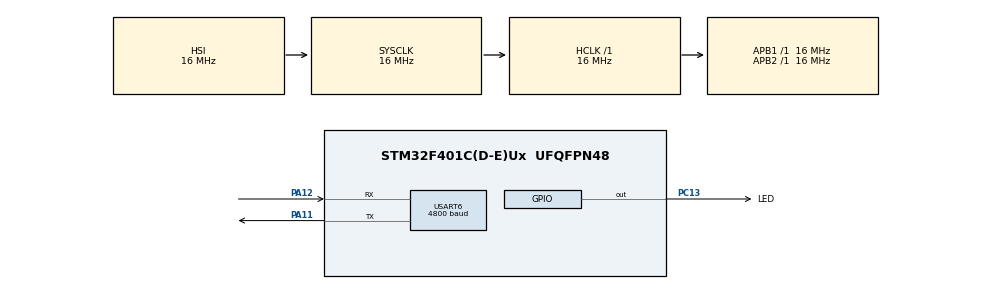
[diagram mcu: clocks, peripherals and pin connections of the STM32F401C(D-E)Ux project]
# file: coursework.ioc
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Mcu.Family=STM32F4
Mcu.Name=STM32F401C(D-E)Ux
Mcu.Package=UFQFPN48
NVIC.PriorityGroup=NVIC_PRIORITYGROUP_4
NVIC.USART6_IRQn=true\:0\:0\:false\:false\:true\:true\:true\:true
PA11.Mode=Asynchronous
PA11.Signal=USART6_TX
PA12.Mode=Asynchronous
PA12.Signal=USART6_RX
PC13-ANTI_TAMP.GPIO_Label=LED
PC13-ANTI_TAMP.GPIO_PuPd=GPIO_NOPULL
PC13-ANTI_TAMP.PinState=GPIO_PIN_RESET
PC13-ANTI_TAMP.Signal=GPIO_Output
ProjectManager.HeapSize=0x200
ProjectManager.StackSize=0x400
ProjectManager.TargetToolchain=STM32CubeIDE
RCC.AHBFreq_Value=16000000
RCC.APB1Freq_Value=16000000
RCC.APB2Freq_Value=16000000
RCC.CortexFreq_Value=16000000
RCC.HSE_VALUE=25000000
RCC.HSI_VALUE=16000000
RCC.LSE_VALUE=32768
RCC.SYSCLKFreq_VALUE=16000000
RCC.VCOOutputFreq_Value=192000000
USART6.BaudRate=4800
USART6.Parity=PARITY_EVEN
USART6.VirtualMode=VM_ASYNC
board=custom

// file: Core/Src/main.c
/* USER CODE BEGIN Header */
/**
  ******************************************************************************
  * @file           : main.c
  * @brief          : Main program body
  ******************************************************************************
  * @attention
  *
  * Copyright (c) 2023 STMicroelectronics.
  * All rights reserved.
  *
  * This software is licensed under terms that can be found in the LICENSE file
  * in the root directory of this software component.
  * If no LICENSE file comes with this software, it is provided AS-IS.
  *
  ******************************************************************************
  */
/* USER CODE END Header */
#include "main.h"

/* USER CODE BEGIN Includes */
#include "stdint.h"
/* USER CODE END Includes */

UART_HandleTypeDef huart6;

void SystemClock_Config(void);
static void MX_GPIO_Init(void);
static void MX_USART6_UART_Init(void);

int main(void)
{

  /* MCU Configuration--------------------------------------------------------*/

  /* Reset of all peripherals, Initializes the Flash interface and the Systick. */
  HAL_Init();

  /* USER CODE BEGIN Init */
  void print(const uint8_t * val, const uint8_t size){
  	  HAL_UART_Transmit_IT(&huart6, val, size);
  	  while( HAL_UART_GetState(&huart6) == HAL_UART_STATE_BUSY_TX );
  }

  void read(uint8_t * val, const uint8_t size){
  	  HAL_UART_Receive_IT(&huart6, val, size);
  	  while( HAL_UART_GetState(&huart6) == HAL_UART_STATE_BUSY_RX );
  }

  /* USER CODE END Init */

  /* Configure the system clock */
  SystemClock_Config();

  /* Initialize all configured peripherals */
  MX_GPIO_Init();
  MX_USART6_UART_Init();
  /* USER CODE BEGIN 2 */

  uint8_t output1[] = "\r\n*----------------------------------------------------*\r\nSelect work mode:"
		  "\r\n1.Switch led on"
		  "\r\n2.Switch led off"
		  "\r\n3.Blink led n times"
		  "\r\n4.Blink led n times with given periodicity"
		  "\r\n5.Exit the program"
		  "\r\nEnter an integer for work mode: ";
  uint8_t output2[] = "\r\nEnter an integer for n(<9): ";
  uint8_t output3[] = "\r\nYour input: ";
  uint8_t output4[] = "\r\n\r\nError: Incorrect input";
  uint8_t output5[] = "\r\nPress any key to continue...";
  uint8_t output6[] = "\r\nHow many times?:";
  uint8_t output7[] = "\r\nHow fast? (N*100 ms):";
  uint8_t input;
  uint8_t n;
  uint8_t x;

  /* USER CODE END 2 */

  /* Infinite loop */
  /* USER CODE BEGIN WHILE */
  HAL_GPIO_WritePin(LED_GPIO_Port, LED_Pin, GPIO_PIN_SET);
  while (1)
  {
	  print(output1, sizeof(output1));

	  read(&input, 1);

	  print(output3, sizeof(output3));
	  print(&input, 1);

	  if(input == '5')
		  break;

	  switch(input){
		  case '1':
			  HAL_GPIO_WritePin(LED_GPIO_Port, LED_Pin, GPIO_PIN_RESET);
			  break;

		  case '2':
			  HAL_GPIO_WritePin(LED_GPIO_Port, LED_Pin, GPIO_PIN_SET);
			  break;

		  case '3':
			  print(output2, sizeof(output2));
			  read(&n, 1);
			  print(output3, sizeof(output3));
			  print(&n, 1);
			  x = n-'0';
			  //HAL_GPIO_WritePin(LED_GPIO_Port, LED_Pin, GPIO_PIN_SET);
			  for(int i = 0; i < x; i++){
				  HAL_GPIO_WritePin(LED_GPIO_Port, LED_Pin, GPIO_PIN_SET);
				  HAL_Delay(500);
				  HAL_GPIO_WritePin(LED_GPIO_Port, LED_Pin, GPIO_PIN_RESET);
				  HAL_Delay(500);
			  }
			  HAL_GPIO_WritePin(LED_GPIO_Port, LED_Pin, GPIO_PIN_SET);
			  break;

		  case '4':
			  print(output6, sizeof(output6));
			  read(&n, 1);
			  print(output3, sizeof(output3));
			  print(&n, 1);
			  x = n - '0';

			  uint8_t per, per1;
			  print(output7, sizeof(output7));
			  read(&per, 1);
			  print(output3, sizeof(output3));
			  print(&per, 1);
			  per1 = per - '0';

			  for(int i = 0; i < x; i++){
				  HAL_GPIO_WritePin(LED_GPIO_Port, LED_Pin, GPIO_PIN_SET);
				  HAL_Delay(per1*100);
				  HAL_GPIO_WritePin(LED_GPIO_Port, LED_Pin, GPIO_PIN_RESET);
				  HAL_Delay(per1*100);
			  }
			  HAL_GPIO_WritePin(LED_GPIO_Port, LED_Pin, GPIO_PIN_SET);
			  break;

		  default:
			  print(output4, sizeof(output4));			//Incorrect input
			  continue;
	  }

	  print(output5, sizeof(output5));					//Press any key

	  read(&input, 1);

    /* USER CODE END WHILE */

  }
}

void SystemClock_Config(void)
{
  RCC_OscInitTypeDef RCC_OscInitStruct = {0};
  RCC_ClkInitTypeDef RCC_ClkInitStruct = {0};

  /** Configure the main internal regulator output voltage
  */
  __HAL_RCC_PWR_CLK_ENABLE();
  __HAL_PWR_VOLTAGESCALING_CONFIG(PWR_REGULATOR_VOLTAGE_SCALE2);

  /** Initializes the RCC Oscillators according to the specified parameters
  * in the RCC_OscInitTypeDef structure.
  */
  RCC_OscInitStruct.OscillatorType = RCC_OSCILLATORTYPE_HSI;
  RCC_OscInitStruct.HSIState = RCC_HSI_ON;
  RCC_OscInitStruct.HSICalibrationValue = RCC_HSICALIBRATION_DEFAULT;
  RCC_OscInitStruct.PLL.PLLState = RCC_PLL_NONE;
  if (HAL_RCC_OscConfig(&RCC_OscInitStruct) != HAL_OK)
  {
    Error_Handler();
  }

  /** Initializes the CPU, AHB and APB buses clocks
  */
  RCC_ClkInitStruct.ClockType = RCC_CLOCKTYPE_HCLK|RCC_CLOCKTYPE_SYSCLK
                              |RCC_CLOCKTYPE_PCLK1|RCC_CLOCKTYPE_PCLK2;
  RCC_ClkInitStruct.SYSCLKSource = RCC_SYSCLKSOURCE_HSI;
  RCC_ClkInitStruct.AHBCLKDivider = RCC_SYSCLK_DIV1;
  RCC_ClkInitStruct.APB1CLKDivider = RCC_HCLK_DIV1;
  RCC_ClkInitStruct.APB2CLKDivider = RCC_HCLK_DIV1;

  if (HAL_RCC_ClockConfig(&RCC_ClkInitStruct, FLASH_LATENCY_0) != HAL_OK)
  {
    Error_Handler();
  }
}

static void MX_USART6_UART_Init(void)
{

  huart6.Instance = USART6;
  huart6.Init.BaudRate = 4800;
  huart6.Init.WordLength = UART_WORDLENGTH_8B;
  huart6.Init.StopBits = UART_STOPBITS_1;
  huart6.Init.Parity = UART_PARITY_EVEN;
  huart6.Init.Mode = UART_MODE_TX_RX;
  huart6.Init.HwFlowCtl = UART_HWCONTROL_NONE;
  huart6.Init.OverSampling = UART_OVERSAMPLING_16;
  if (HAL_UART_Init(&huart6) != HAL_OK)
  {
    Error_Handler();
  }

}

static void MX_GPIO_Init(void)
{
  GPIO_InitTypeDef GPIO_InitStruct = {0};

  /* GPIO Ports Clock Enable */
  __HAL_RCC_GPIOC_CLK_ENABLE();
  __HAL_RCC_GPIOA_CLK_ENABLE();

  /*Configure GPIO pin Output Level */
  HAL_GPIO_WritePin(LED_GPIO_Port, LED_Pin, GPIO_PIN_RESET);

  /*Configure GPIO pin : LED_Pin */
  GPIO_InitStruct.Pin = LED_Pin;
  GPIO_InitStruct.Mode = GPIO_MODE_OUTPUT_PP;
  GPIO_InitStruct.Pull = GPIO_NOPULL;
  GPIO_InitStruct.Speed = GPIO_SPEED_FREQ_LOW;
  HAL_GPIO_Init(LED_GPIO_Port, &GPIO_InitStruct);

}

void Error_Handler(void)
{
  __disable_irq();
  while (1)
  {
  }
}
